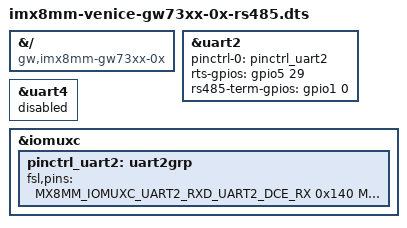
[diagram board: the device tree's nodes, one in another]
// SPDX-License-Identifier: (GPL-2.0+ OR MIT)
/*
 * Copyright 2021 Gateworks Corporation
 */

#include <dt-bindings/gpio/gpio.h>

#include "imx8mm-pinfunc.h"

/dts-v1/;
/plugin/;

&{/} {
	compatible = "gw,imx8mm-gw73xx-0x";
};

/* For RS485 HD:
 *  - UART4_TX is DE for RS485 transmitter
 *  - RS485_EN needs to be pulled high
 *  - RS485_HALF needs to be pulled high
 */
&uart2 {
	pinctrl-names = "default";
	pinctrl-0 = <&pinctrl_uart2>;
	rts-gpios = <&gpio5 29 GPIO_ACTIVE_HIGH>;
	rs485-term-gpios = <&gpio1 0 GPIO_ACTIVE_HIGH>;
	status = "okay";
};

&uart4 {
	status = "disabled";
};

&iomuxc {
	pinctrl_uart2: uart2grp {
		fsl,pins = <
			MX8MM_IOMUXC_UART2_RXD_UART2_DCE_RX     0x140
			MX8MM_IOMUXC_UART2_TXD_UART2_DCE_TX     0x140
			MX8MM_IOMUXC_UART4_TXD_GPIO5_IO29	0x140
			MX8MM_IOMUXC_GPIO1_IO00_GPIO1_IO0       0x40000104 /* RS485_TERM */
			MX8MM_IOMUXC_SAI1_RXFS_GPIO4_IO0        0x40000144 /* RS485_EN */
			MX8MM_IOMUXC_SAI1_RXD0_GPIO4_IO2        0x40000144 /* RS485_HALF */
		>;
	};
};
